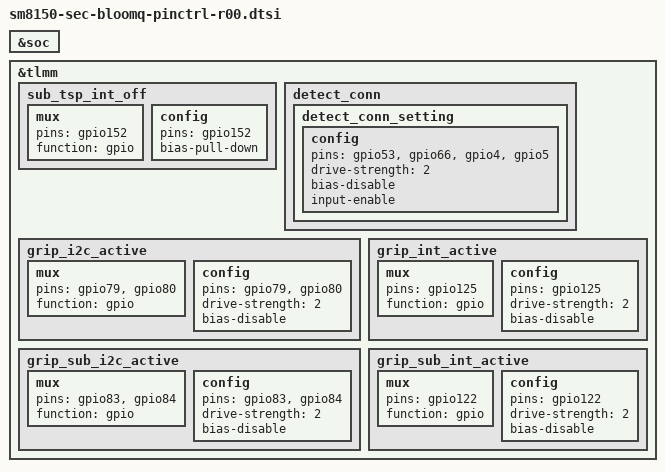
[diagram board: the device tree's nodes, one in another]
/* Copyright (c) 2016-2017, The Linux Foundation. All rights reserved.
 *
 * This program is free software; you can redistribute it and/or modify
 * it under the terms of the GNU General Public License version 2 and
 * only version 2 as published by the Free Software Foundation.
 *
 * This program is distributed in the hope that it will be useful,
 * but WITHOUT ANY WARRANTY; without even the implied warranty of
 * MERCHANTABILITY or FITNESS FOR A PARTICULAR PURPOSE.  See the
 * GNU General Public License for more details.
 */

#include "sm8150-sec-bloomq-pinctrl-common.dtsi"

&soc {
	/* tlmm: pinctrl@03400000 { }; */
};

&tlmm {
	sub_tsp_int_off {
		mux {
			pins = "gpio152";
			function = "gpio";
		};
		config {
			pins = "gpio152";
			bias-pull-down;
		};
	};

	detect_conn {
		detect_conn_setting: detect_conn_setting {
			config {
				pins = "gpio53", "gpio66", "gpio4", "gpio5";
				drive-strength = <2>;
				bias-disable; /* No PULL */
				input-enable;
			};
		};
	};
	grip_i2c_active: grip_i2c_active {
		mux {
			pins = "gpio79", "gpio80";
			function = "gpio";
		};
		config {
			pins = "gpio79", "gpio80";
			drive-strength = <2>;
			bias-disable;
		};
	};

	grip_int_active: grip_int_active {
		mux {
			pins = "gpio125";
			function = "gpio";
		};
		config {
			pins = "gpio125";
			drive-strength = <2>;
			bias-disable;
		};
	};

	grip_sub_i2c_active: grip_sub_i2c_active {
		mux {
			pins = "gpio83", "gpio84";
			function = "gpio";
		};
		config {
			pins = "gpio83", "gpio84";
			drive-strength = <2>;
			bias-disable;
		};
	};

	grip_sub_int_active: grip_sub_int_active {
		mux {
			pins = "gpio122";
			function = "gpio";
		};
		config {
			pins = "gpio122";
			drive-strength = <2>;
			bias-disable;
		};
	};
};
